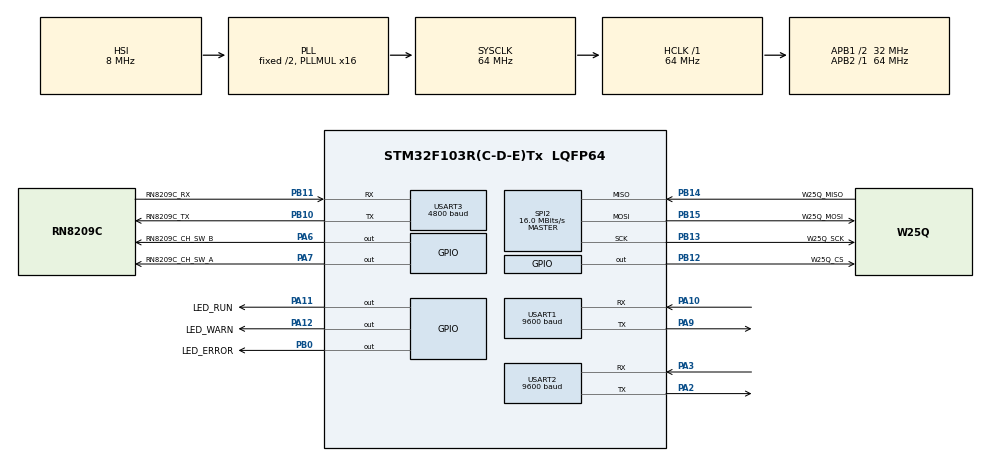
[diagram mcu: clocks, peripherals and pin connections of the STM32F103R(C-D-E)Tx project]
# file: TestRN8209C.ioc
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Dma.Request0=USART3_RX
Dma.Request1=USART3_TX
Dma.Request2=USART1_RX
Dma.Request3=USART1_TX
Dma.Request4=USART2_RX
Dma.Request5=USART2_TX
Dma.USART1_RX.2.Direction=DMA_PERIPH_TO_MEMORY
Dma.USART1_RX.2.Instance=DMA1_Channel5
Dma.USART1_RX.2.MemDataAlignment=DMA_MDATAALIGN_BYTE
Dma.USART1_RX.2.MemInc=DMA_MINC_ENABLE
Dma.USART1_RX.2.Mode=DMA_NORMAL
Dma.USART1_RX.2.PeriphDataAlignment=DMA_PDATAALIGN_BYTE
Dma.USART1_RX.2.PeriphInc=DMA_PINC_DISABLE
Dma.USART1_RX.2.Priority=DMA_PRIORITY_LOW
Dma.USART1_TX.3.Direction=DMA_MEMORY_TO_PERIPH
Dma.USART1_TX.3.Instance=DMA1_Channel4
Dma.USART1_TX.3.MemDataAlignment=DMA_MDATAALIGN_BYTE
Dma.USART1_TX.3.MemInc=DMA_MINC_ENABLE
Dma.USART1_TX.3.Mode=DMA_NORMAL
Dma.USART1_TX.3.PeriphDataAlignment=DMA_PDATAALIGN_BYTE
Dma.USART1_TX.3.PeriphInc=DMA_PINC_DISABLE
Dma.USART1_TX.3.Priority=DMA_PRIORITY_LOW
Dma.USART2_RX.4.Direction=DMA_PERIPH_TO_MEMORY
Dma.USART2_RX.4.Instance=DMA1_Channel6
Dma.USART2_RX.4.MemDataAlignment=DMA_MDATAALIGN_BYTE
Dma.USART2_RX.4.MemInc=DMA_MINC_ENABLE
Dma.USART2_RX.4.Mode=DMA_NORMAL
Dma.USART2_RX.4.PeriphDataAlignment=DMA_PDATAALIGN_BYTE
Dma.USART2_RX.4.PeriphInc=DMA_PINC_DISABLE
Dma.USART2_RX.4.Priority=DMA_PRIORITY_LOW
Dma.USART2_TX.5.Direction=DMA_MEMORY_TO_PERIPH
Dma.USART2_TX.5.Instance=DMA1_Channel7
Dma.USART2_TX.5.MemDataAlignment=DMA_MDATAALIGN_BYTE
Dma.USART2_TX.5.MemInc=DMA_MINC_ENABLE
Dma.USART2_TX.5.Mode=DMA_NORMAL
Dma.USART2_TX.5.PeriphDataAlignment=DMA_PDATAALIGN_BYTE
Dma.USART2_TX.5.PeriphInc=DMA_PINC_DISABLE
Dma.USART2_TX.5.Priority=DMA_PRIORITY_LOW
Dma.USART3_RX.0.Direction=DMA_PERIPH_TO_MEMORY
Dma.USART3_RX.0.Instance=DMA1_Channel3
Dma.USART3_RX.0.MemDataAlignment=DMA_MDATAALIGN_BYTE
Dma.USART3_RX.0.MemInc=DMA_MINC_ENABLE
Dma.USART3_RX.0.Mode=DMA_NORMAL
Dma.USART3_RX.0.PeriphDataAlignment=DMA_PDATAALIGN_BYTE
Dma.USART3_RX.0.PeriphInc=DMA_PINC_DISABLE
Dma.USART3_RX.0.Priority=DMA_PRIORITY_LOW
Dma.USART3_TX.1.Direction=DMA_MEMORY_TO_PERIPH
Dma.USART3_TX.1.Instance=DMA1_Channel2
Dma.USART3_TX.1.MemDataAlignment=DMA_MDATAALIGN_BYTE
Dma.USART3_TX.1.MemInc=DMA_MINC_ENABLE
Dma.USART3_TX.1.Mode=DMA_NORMAL
Dma.USART3_TX.1.PeriphDataAlignment=DMA_PDATAALIGN_BYTE
Dma.USART3_TX.1.PeriphInc=DMA_PINC_DISABLE
Dma.USART3_TX.1.Priority=DMA_PRIORITY_LOW
IWDG.Prescaler=IWDG_PRESCALER_64
Mcu.Family=STM32F1
Mcu.Name=STM32F103R(C-D-E)Tx
Mcu.Package=LQFP64
NVIC.DMA1_Channel2_IRQn=true\:0\:0\:false\:false\:true\:false\:true\:true
NVIC.DMA1_Channel3_IRQn=true\:0\:0\:false\:false\:true\:false\:true\:true
NVIC.DMA1_Channel4_IRQn=true\:0\:0\:false\:false\:true\:false\:true\:true
NVIC.DMA1_Channel5_IRQn=true\:0\:0\:false\:false\:true\:false\:true\:true
NVIC.DMA1_Channel6_IRQn=true\:0\:0\:false\:false\:true\:false\:true\:true
NVIC.DMA1_Channel7_IRQn=true\:0\:0\:false\:false\:true\:false\:true\:true
NVIC.PriorityGroup=NVIC_PRIORITYGROUP_4
NVIC.TIM6_IRQn=true\:0\:0\:false\:false\:true\:true\:true\:true
NVIC.TIM7_IRQn=true\:0\:0\:false\:false\:true\:true\:true\:true
NVIC.USART1_IRQn=true\:0\:0\:false\:false\:true\:true\:true\:true
NVIC.USART2_IRQn=true\:0\:0\:false\:false\:true\:true\:true\:true
NVIC.USART3_IRQn=true\:0\:0\:false\:false\:true\:true\:true\:true
PA10.GPIO_PuPd=GPIO_PULLUP
PA10.Mode=Asynchronous
PA10.Signal=USART1_RX
PA11.GPIO_Label=LED_RUN
PA11.GPIO_PuPd=GPIO_PULLUP
PA11.GPIO_Speed=GPIO_SPEED_FREQ_HIGH
PA11.PinState=GPIO_PIN_SET
PA11.Signal=GPIO_Output
PA12.GPIO_Label=LED_WARN
PA12.GPIO_PuPd=GPIO_PULLUP
PA12.GPIO_Speed=GPIO_SPEED_FREQ_HIGH
PA12.PinState=GPIO_PIN_SET
PA12.Signal=GPIO_Output
PA13.Mode=Serial_Wire
PA13.Signal=SYS_JTMS-SWDIO
PA14.Mode=Serial_Wire
PA14.Signal=SYS_JTCK-SWCLK
PA2.Mode=Asynchronous
PA2.Signal=USART2_TX
PA3.GPIO_PuPd=GPIO_PULLUP
PA3.Mode=Asynchronous
PA3.Signal=USART2_RX
PA6.GPIO_Label=RN8209C_CH_SW_B
PA6.GPIO_PuPd=GPIO_PULLDOWN
PA6.GPIO_Speed=GPIO_SPEED_FREQ_HIGH
PA6.Signal=GPIO_Output
PA7.GPIO_Label=RN8209C_CH_SW_A
PA7.GPIO_PuPd=GPIO_PULLDOWN
PA7.GPIO_Speed=GPIO_SPEED_FREQ_HIGH
PA7.Signal=GPIO_Output
PA9.Mode=Asynchronous
PA9.Signal=USART1_TX
PB0.GPIO_Label=LED_ERROR
PB0.GPIO_PuPd=GPIO_PULLUP
PB0.GPIO_Speed=GPIO_SPEED_FREQ_HIGH
PB0.PinState=GPIO_PIN_SET
PB0.Signal=GPIO_Output
PB10.GPIO_Label=RN8209C_TX
PB10.Mode=Asynchronous
PB10.Signal=USART3_TX
PB11.GPIO_Label=RN8209C_RX
PB11.GPIO_PuPd=GPIO_PULLUP
PB11.Mode=Asynchronous
PB11.Signal=USART3_RX
PB12.GPIO_Label=W25Q_CS
PB12.GPIO_PuPd=GPIO_PULLUP
PB12.GPIO_Speed=GPIO_SPEED_FREQ_HIGH
PB12.PinState=GPIO_PIN_SET
PB12.Signal=GPIO_Output
PB13.GPIO_Label=W25Q_SCK
PB13.Mode=Full_Duplex_Master
PB13.Signal=SPI2_SCK
PB14.GPIO_Label=W25Q_MISO
PB14.Mode=Full_Duplex_Master
PB14.Signal=SPI2_MISO
PB15.GPIO_Label=W25Q_MOSI
PB15.Mode=Full_Duplex_Master
PB15.Signal=SPI2_MOSI
ProjectManager.HeapSize=0x00
ProjectManager.StackSize=0x2400
ProjectManager.TargetToolchain=MDK-ARM V5.32
RCC.AHBFreq_Value=64000000
RCC.APB1CLKDivider=RCC_HCLK_DIV2
RCC.APB1Freq_Value=32000000
RCC.APB1TimFreq_Value=64000000
RCC.APB2Freq_Value=64000000
RCC.APB2TimFreq_Value=64000000
RCC.HCLKFreq_Value=64000000
RCC.PLLMUL=RCC_PLL_MUL16
RCC.SYSCLKFreq_VALUE=64000000
RCC.SYSCLKSource=RCC_SYSCLKSOURCE_PLLCLK
RCC.USBFreq_Value=64000000
SPI2.CLKPhase=SPI_PHASE_2EDGE
SPI2.CLKPolarity=SPI_POLARITY_HIGH
SPI2.CalculateBaudRate=16.0 MBits/s
SPI2.Direction=SPI_DIRECTION_2LINES
SPI2.Mode=SPI_MODE_MASTER
SPI2.VirtualType=VM_MASTER
TIM6.Period=2000-1
TIM6.Prescaler=6400-1
TIM7.Period=6000-1
TIM7.Prescaler=6400-1
USART1.BaudRate=9600
USART1.VirtualMode=VM_ASYNC
USART2.BaudRate=9600
USART2.VirtualMode=VM_ASYNC
USART3.BaudRate=4800
USART3.Parity=PARITY_EVEN
USART3.VirtualMode=VM_ASYNC
USART3.WordLength=WORDLENGTH_9B
VP_IWDG_VS_IWDG.Mode=IWDG_Activate
VP_TIM6_VS_ClockSourceINT.Mode=Enable_Timer
VP_TIM7_VS_ClockSourceINT.Mode=Enable_Timer
board=custom

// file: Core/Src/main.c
/* USER CODE BEGIN Header */
/**
  ******************************************************************************
  * @file           : main.c
  * @brief          : Main program body
  ******************************************************************************
  * @attention
  *
  * Copyright (c) 2023 STMicroelectronics.
  * All rights reserved.
  *
  * This software is licensed under terms that can be found in the LICENSE file
  * in the root directory of this software component.
  * If no LICENSE file comes with this software, it is provided AS-IS.
  *
  ******************************************************************************
  */
/* USER CODE END Header */
#include "main.h"
#include "dma.h"
#include "iwdg.h"
#include "spi.h"
#include "tim.h"
#include "usart.h"
#include "gpio.h"

/* USER CODE BEGIN Includes */
#include "app_init_variables.h"
#include "RN8209C_main.h"
#include "V9240_main.h"
#include "app_uart_rcv.h"
#include "app_led.h"
#include "app_storage.h"
/* USER CODE END Includes */

void SystemClock_Config(void);

int main(void)
{
  /* USER CODE BEGIN 1 */
  Init_Variables();
  /* USER CODE END 1 */

  /* MCU Configuration--------------------------------------------------------*/

  /* Reset of all peripherals, Initializes the Flash interface and the Systick. */
  HAL_Init();

  /* Configure the system clock */
  SystemClock_Config();

  /* Initialize all configured peripherals */
  MX_GPIO_Init();
  MX_DMA_Init();
  //MX_IWDG_Init();
  MX_USART3_UART_Init();
  MX_USART1_UART_Init();
  MX_USART2_UART_Init();
  MX_SPI2_Init();
  MX_TIM7_Init();
  MX_TIM6_Init();
  /* USER CODE BEGIN 2 */

  HAL_Delay(TIME_2S);
  Storage_Init();
  /* USER CODE END 2 */

  /* Infinite loop */
  /* USER CODE BEGIN WHILE */
  while (1)
  {
    RN8209C_Handler();
    V9240_Handler();
    Uart_Handler();
    LED_Handler();
    Storage_Handler();
    /* USER CODE END WHILE */

  }
}

void SystemClock_Config(void)
{
  RCC_OscInitTypeDef RCC_OscInitStruct = {0};
  RCC_ClkInitTypeDef RCC_ClkInitStruct = {0};

  /** Initializes the RCC Oscillators according to the specified parameters
  * in the RCC_OscInitTypeDef structure.
  */
  RCC_OscInitStruct.OscillatorType = RCC_OSCILLATORTYPE_HSI|RCC_OSCILLATORTYPE_LSI;
  RCC_OscInitStruct.HSIState = RCC_HSI_ON;
  RCC_OscInitStruct.HSICalibrationValue = RCC_HSICALIBRATION_DEFAULT;
  RCC_OscInitStruct.LSIState = RCC_LSI_ON;
  RCC_OscInitStruct.PLL.PLLState = RCC_PLL_ON;
  RCC_OscInitStruct.PLL.PLLSource = RCC_PLLSOURCE_HSI_DIV2;
  RCC_OscInitStruct.PLL.PLLMUL = RCC_PLL_MUL16;
  if (HAL_RCC_OscConfig(&RCC_OscInitStruct) != HAL_OK)
  {
    Error_Handler();
  }

  /** Initializes the CPU, AHB and APB buses clocks
  */
  RCC_ClkInitStruct.ClockType = RCC_CLOCKTYPE_HCLK|RCC_CLOCKTYPE_SYSCLK
                              |RCC_CLOCKTYPE_PCLK1|RCC_CLOCKTYPE_PCLK2;
  RCC_ClkInitStruct.SYSCLKSource = RCC_SYSCLKSOURCE_PLLCLK;
  RCC_ClkInitStruct.AHBCLKDivider = RCC_SYSCLK_DIV1;
  RCC_ClkInitStruct.APB1CLKDivider = RCC_HCLK_DIV2;
  RCC_ClkInitStruct.APB2CLKDivider = RCC_HCLK_DIV1;

  if (HAL_RCC_ClockConfig(&RCC_ClkInitStruct, FLASH_LATENCY_2) != HAL_OK)
  {
    Error_Handler();
  }
}

void Error_Handler(void)
{
  __disable_irq();
  while (1)
  {
  }
}
